# ISP_PREVIEW register map
Vendor: Texas Instruments
Peripheral module from a debugger description file (folder omap36xx).
Registers are 32-bit, read-write, reset 0x0 unless marked. A register's access mark holds for its fields unless they carry their own. Offsets are as the file gives them; lines under a group give offsets from that group; [hi:lo] are bit positions; {n}, {i} and the like mark numbered series; 'fields as' and 'values as' point back to an identical list; <NAME> marks a mode.

## ISP_PREVIEW
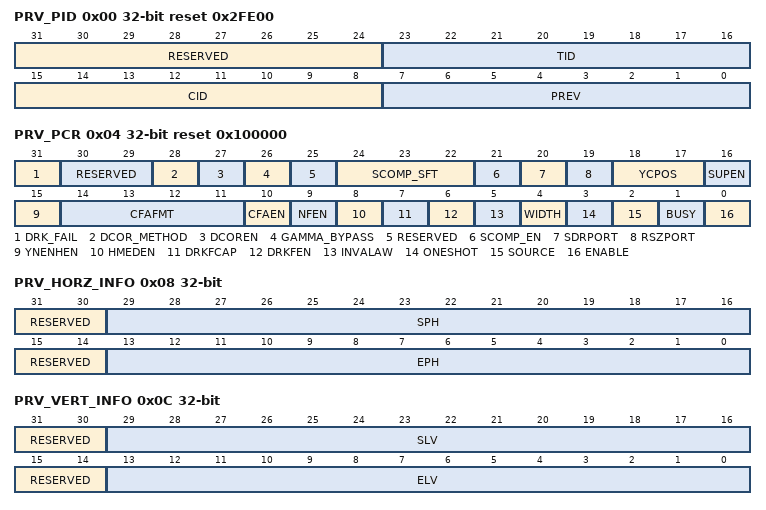
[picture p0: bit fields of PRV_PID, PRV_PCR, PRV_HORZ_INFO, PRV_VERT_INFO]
0x00 PRV_PID ro reset 0x2FE00 (reset mask 0xFFFFFF00) — PERIPHERAL ID REGISTER
  [31:24] RESERVED — Write 0s for future compatibility. Reads returns 0.
  [23:16] TID — Peripheral identification: PRV module
  [15:8] CID — Class identification: Camera ISP
  [7:0] PREV — Peripheral revision number
0x04 PRV_PCR access per field reset 0x100000 — PERIPHERAL CONTROL REGISTER All the fields in this register can be altered even when the PREVIEW module is busy. Changes take place only for the next frame.
  [31] DRK_FAIL rw — Dark frame subtract fail status. Write 1 to clear this bit. Reset to zero for the next frame. When the error is triggered, dark frame subtract is abandoned for the current frame, dark frame subtract resumes for next frame (but bit is not cleared unless explicitly done by firmware).
    0=No error; 1=Error
  [30:29] RESERVED rw — Write 0s for future compatibility.Reads returns 0.
  [28] DCOR_METHOD rw — Defect correction method.
    0=MinMax; 1=MinMax2 (Couplet defect correction)
  [27] DCOREN rw — Defect correction enable This bit enables or disables the defect correction. The PRV_PCR.DCOR_METHOD and PRV_CDC_THRx registers must be configured for correct operation.
    0=Disable defect correction; 1=Enable defect correction
  [26] GAMMA_BYPASS rw — Bypass, the output is set to the 8 MSB of the 10-bit input.
    0=No bypass; 1=Bypass, the output is set to the 8 MSB of the 10-bit input
  [25] RESERVED rw — Write 0s for future compatibility.Reads returns 0.
  [24:22] SCOMP_SFT rw — Shading compensation shift value after multiplication. The right-shift range is 0 to 7.
  [21] SCOMP_EN rw — Shading compensation enable instead of dark frame The 8-bit value loaded from memory is multiplied by the current pixel instead of subtracting it. Note that the dark frame subtract (DRKFEN) must be enabled in addition to this bit being active to perform shading compensation.
    0=Disable. Dark frame subtract can be used.; 1=Enable. Dark frame subtract cannot be used.
  [20] SDRPORT rw — PREVIEW module memory output port enable. This bit enables or disables the data transfer from the PREVIEW module to the memory.
    0=Disable; 1=Enable
  [19] RSZPORT rw — RESIZER module output port enable. This bit enables or disables the data transfer between the PREVIEW and RESIZER modules. Controls whether or not SDRAM output data is forwarded to the resizer input port. This control bit does not depend on the state of the former SDRPORT bit. Data is simultaneously written to SDRAM (if SDRPORT bit is set) while sending the same data to the resizer as input. Note that the CCDC is also capable or directly writing to the resizer input port. The CCDC setting takes precedence over the preview engine setting.
    0=Disable; 1=Enable
  [18:17] YCPOS rw — (CRYCBY) Cr0(31:24) Y1(23:16) Cb0(15:8) Y0(7:0)
    0=(YCRYCB) Y1(31:24) Cr0(23:16) Y0(15:8) Cb0(7:0); 1=(YCBYCR) Y1(31:24) Cb0(23:16) Y0(15:8) Cr0(7:0); 2=(CBYCRY) Cb0(31:24) Y1(23:16) Cr(15:8) Y0(7:0); 3=(CRYCBY) Cr0(31:24) Y1(23:16) Cb0(15:8) Y0(7:0)
  [16] SUPEN rw — Color suppression.
    0=Disable; 1=Enable
  [15] YNENHEN rw — Non-linear enhancer
    0=Disable; 1=Enable
  [14:11] CFAFMT rw — CFA format
    0=Mode 0: conventional Bayer; 1=Mode 1: horizontal 2x downsample; 2=Mode 2: bypass CFA stage; 3=Mode 3: horizontal and vertical 2x downsample; 4=Mode 4: Super CCD Honeycom movie mode sensor; 5=Mode5: bypass CFA stage 
  [10] CFAEN rw — CFA enable
    0=Disable; 1=Enable
  [9] NFEN rw — Noise filter enable
    0=Disable; 1=Enable
  [8] HMEDEN rw — Horizontal median filter enable.
    0=Disable; 1=Enable
  [7] DRKFCAP rw — Dark frame capture enable.
    0=Normal processing; 1=Capture dark frame
  [6] DRKFEN rw — Subtract dark frame enable.
    0=Disable; 1=Enable
  [5] INVALAW rw — Inverse A-Law enable.
    0=Disable; 1=Enable
  [4] WIDTH rw — Input data width selection.
    0=10-bit mode; 1=8-bit mode
  [3] ONESHOT rw — One-shot mode selection.If this bit is set to 1, it is reset to 0 after the ENABLE bit is asserted.
    0=Continuous mode (through the video port); 1=One shot mode
  [2] SOURCE rw — Input source selection.If this bit is set to 1, it is reset to 0 after the ENABLE bit is asserted.
    0=Video port (through the CCDC); 1=Memory
  [1] BUSY ro — Busy bit.
    0=PREVIEW module not busy; 1=PREVIEW module busy
  [0] ENABLE rw — Enable bit.If the ONESHOT or SOURCE bit is 1, this bit is reset to 0 after it is asserted
    0=PREVIEW module disabled; 1=PREVIEW module enabled
0x08 PRV_HORZ_INFO — HORIZONTAL SETUP REGISTER
  [31:30] RESERVED — Write 0s for future compatibility.Reads returns 0.
  [29:16] SPH — Start pixel horizontal.If PRV_PCR.SOURCE == 0 (CCDC input) SPH must be = 2.
  [15:14] RESERVED — Write 0s for future compatibility.Reads returns 0.
  [13:0] EPH — End pixel horizontal. The input width of the preview engine must be a multiple of the average count multiplied by the least common multiple of the odd distance and even distance of the AVE register settings. If PRV_PCR.SOURCE == 0 (CCDC input) EPH must be = 2 pixels before the last pixel sent from the CCDC. PRV_HORZ_INFO.EPH - PRV_HORZ_INFO.SPH + 1) MOD ((1 PRV_AVE.COUNT) * LeastCommonMultiple(PRV_AVE.ODDDIST+1, PRV_AVE.EVENDIST+1)) = 0
0x0C PRV_VERT_INFO — VERTICAL SETUP REGISTER
  [31:30] RESERVED — Write 0s for future compatibility.Reads returns 0.
  [29:16] SLV — Start line vertical
  [15:14] RESERVED — Write 0s for future compatibility.Reads returns 0.
  [13:0] ELV — End line vertical
0x10 PRV_RSDR_ADDR — MEMORY READ ADDRESS REGISTER
  [31:0] RADR — 32-bit read address. Specifies the 32-bit address in memory of the input frame. The lower 5 bits of this register are always treated as 0s. The offset should be aligned on a 32-byte boundary. This field can be altered even when the PREVIEW module is busy. The change takes place only for the next frame (next VS pulse). However, note that reading this register always gives the latest value.
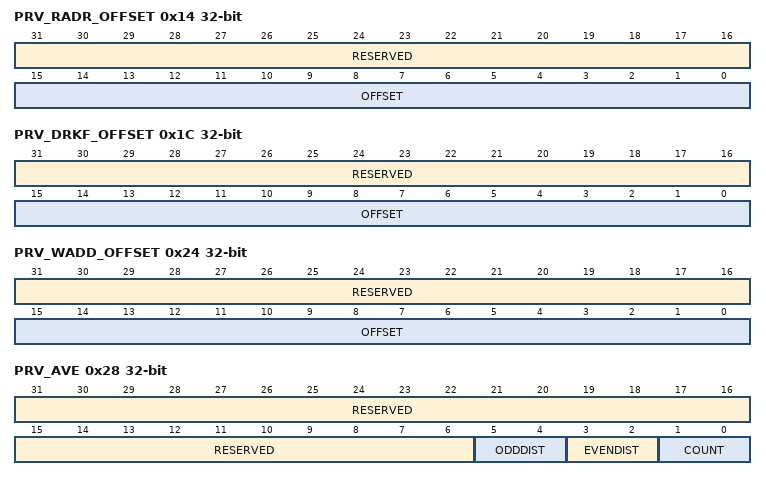
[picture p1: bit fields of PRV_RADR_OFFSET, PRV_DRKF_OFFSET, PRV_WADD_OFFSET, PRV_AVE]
0x14 PRV_RADR_OFFSET — MEMORY READ ADDRESS OFFSET REGISTER
  [31:16] RESERVED — Write 0s for future compatibility.Reads returns 0.
  [15:0] OFFSET — Line offset. Specifies the offset for each line relatively to the previous line. The lower 5 bits of this register are always treated as 0s. The offset should be aligned on a 32-byte boundary. This field can be altered even when the PREVIEW module is busy. The change takes place only for the next frame (next VS sync pulse). However, note that reading this register always gives the latest value.
0x18 PRV_DSDR_ADDR — DARK FRAME MEMORY ADDRESS REGISTER
  [31:0] DRKF — Dark frame address. Specifies the dark frame start address in memory. The lower 5 bits of this register are always treated as 0s. The offset should be aligned on a 32-byte boundary. This field can be altered even when the PREVIEW module is busy. The change takes place only for the next frame (next VS sync pulse). However, note that reading this register always gives the latest value.
0x1C PRV_DRKF_OFFSET — DARK FRAME MEMORY OFFSET REGISTER
  [31:16] RESERVED — Write 0s for future compatibility.Reads returns 0.
  [15:0] OFFSET — Dark frame line offset. Specifies the offset for each line relatively to the previous line. The lower 5 bits of this register are always treated as 0s. The offset should be aligned on a 32-byte boundary. This field can be altered even when the PREVIEW module is busy. The change takes place only for the next frame (next VS pulse). However, note that reading this register always gives the latest value.
0x20 PRV_WSDR_ADDR — MEMORY WRITE ADDRESS REGISTER
  [31:0] ADDR — Write address. Specifies the 32-bit address in memory of the output frame. The lower 5 bits of this register are always treated as 0s. The offset should be aligned on a 32-byte boundary. For optimum performance in the system, the starting address must be on a 256-byte boundary This field can be altered even when the PREVIEW module is busy. The change takes place only for the next frame (next VS pulse). However, note that reading this register always gives the latest value.
0x24 PRV_WADD_OFFSET — MEMORY WRITE OFFSET REGISTER
  [31:16] RESERVED — Write 0s for future compatibility.Reads returns 0.
  [15:0] OFFSET — Line offset. The lower 5 bits of this register are always treated as 0s. The offset should be aligned on a 32-byte boundary. For optimum performance in the system, the starting address must be on a 256-byte boundary This field can be altered even when the PREVIEW module is busy. The change takes place only for the next frame (next VS pulse). However, note that reading this register always gives the latest value.
0x28 PRV_AVE — INPUT FORMATTER REGISTER
  [31:6] RESERVED — Write 0s for future compatibility.Reads returns 0.
  [5:4] ODDDIST — Distance between consecutive pixels of the same color in the odd line.
    {v}={v+1} (v=0..3)
  [3:2] EVENDIST — Distance between consecutive pixels of the same color in the even line.
    {v}={v+1} (v=0..3)
  [1:0] COUNT — Number of horizontal pixels to average. This field should not be changed when the 'PRV_PCR.DRKFEN bit is set to 1 The input width must be divisible by the number of horizontal pixels to average indicated by this field ( if 4 pixel average is selected, then the input width must be a multiple of 4).
    0=No averaging; 1=2-pixel average; 2=4-pixel average; 3=8-pixel average
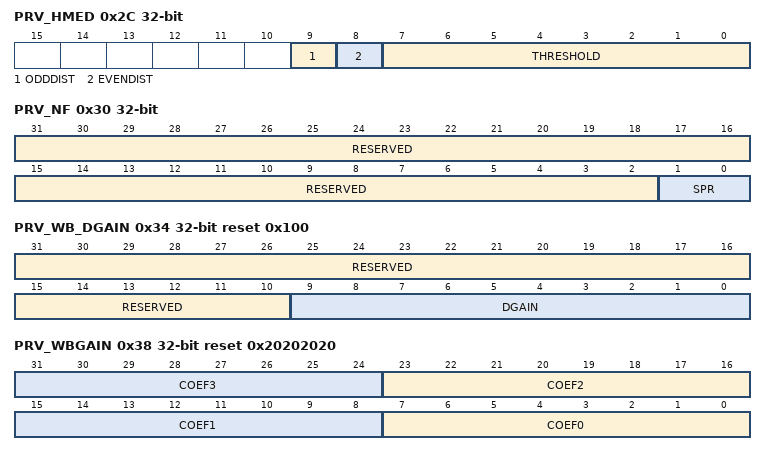
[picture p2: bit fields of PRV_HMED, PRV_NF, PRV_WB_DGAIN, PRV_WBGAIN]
0x2C PRV_HMED — HORIZONTAL MEDIAN FILTER REGISTER
  [9] ODDDIST — Distance between consecutive pixels of the same color in the odd line.
    0=1; 1=2
  [8] EVENDIST — Distance between consecutive pixels of the same color in even line.
    0=1; 1=2
  [7:0] THRESHOLD — Horizontal median filter threshold.
0x30 PRV_NF — NOISE FILTER REGISTER
  [31:2] RESERVED — Write 0s for future compatibility.Reads returns 0.
  [1:0] SPR — The spread value in noise filter algorithm
0x34 PRV_WB_DGAIN reset 0x100 — WHITE BALANCE COEF REGISTER
  [31:10] RESERVED — Write 0s for future compatibility.Reads returns 0.
  [9:0] DGAIN — Digital gain for the white balance. The data is in U10Q8 representation. The value can change anytime following the start of a frame.
0x38 PRV_WBGAIN reset 0x20202020 — WHITE BALANCE COEF REGISTER
  [8n+7:8n] COEF{n} (n=0..3) — White balance gain - COEF{n}. The data is in U8Q5 representation. The value can change anytime following the start of a frame.
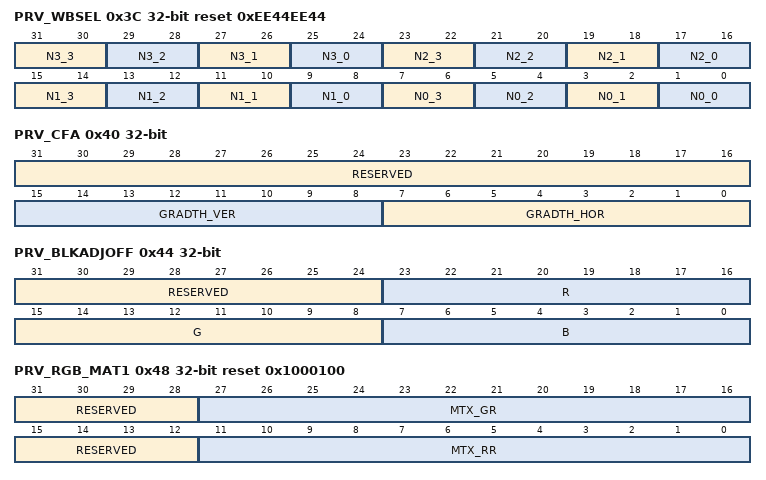
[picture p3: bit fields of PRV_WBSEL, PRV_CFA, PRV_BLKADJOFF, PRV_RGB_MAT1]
0x3C PRV_WBSEL reset 0xEE44EE44 — WHITE BALANCE COEF SELECTION REGISTER
  [all] fields
    {v}=COEF{v} (v=0..3)
  [31:30] N3_3 — Coefficient selection for 3rd line, 3rd pixel.
  [29:28] N3_2 — Coefficient selection for 3rd line, 2rd pixel.
  [27:26] N3_1 — Coefficient selection for 3rd line, 1st pixel.
  [25:24] N3_0 — Coefficient selection for 3rd line, 0th pixel.
  [23:22] N2_3 — Coefficient selection for 2nd line, 3rd pixel.
  [21:20] N2_2 — Coefficient selection for 2nd line, 2nd pixel.
  [19:18] N2_1 — Coefficient selection for 2nd line, 1st pixel.
  [17:16] N2_0 — Coefficient selection for 2nd line, 0th pixel.
  [15:14] N1_3 — Coefficient selection for 1st line, 3rd pixel.
  [13:12] N1_2 — Coefficient selection for 1st line, 2nd pixel.
  [11:10] N1_1 — Coefficient selection for 1st line, 1st pixel.
  [9:8] N1_0 — Coefficient selection for 1st line, 0th pixel.
  [7:6] N0_3 — Coefficient selection for 0th line, 3rd pixel.
  [5:4] N0_2 — Coefficient selection for 0th line, 2nd pixel.
  [3:2] N0_1 — Coefficient selection for 0th line, 1st pixel.
  [1:0] N0_0 — Coefficient selection for 0th line, 0th pixel.
0x40 PRV_CFA — COLOR FILTER ARRAY REGISTER
  [31:16] RESERVED — Write 0s for future compatibility.Reads returns 0.
  [15:8] GRADTH_VER — Gradient threshold vertical.
  [7:0] GRADTH_HOR — Gradient threshold horizontal.
0x44 PRV_BLKADJOFF — BLACK ADJUSTMENT OFFSET REGISTER
  [31:24] RESERVED — Write 0s for future compatibility.Reads returns 0.
  [23:16] R — Black-level offset adjustment for RED. The data is in 2's complement format.
  [15:8] G — Black-level offset adjustment for GREEN. The data is in 2's complement format.
  [7:0] B — Black-level offset adjustment for BLUE. The data is in 2's complement format.
0x48 PRV_RGB_MAT1 reset 0x1000100 — RGB TO RGB MATRIX COEF REGISTER
  [31:28] RESERVED — Write 0s for future compatibility.Reads returns 0.
  [27:16] MTX_GR — Blending value for GR position. The format is in S12Q8 representation.
  [15:12] RESERVED — Write 0s for future compatibility.Reads returns 0.
  [11:0] MTX_RR — Blending value for RR position. The format is in S12Q8 representation.
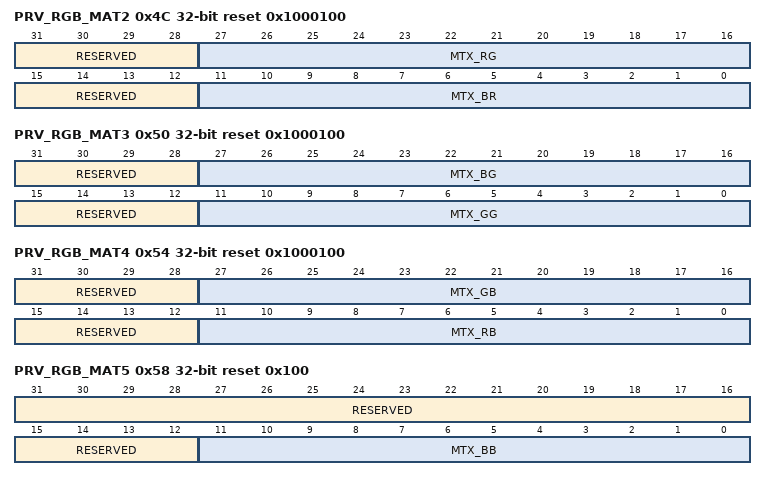
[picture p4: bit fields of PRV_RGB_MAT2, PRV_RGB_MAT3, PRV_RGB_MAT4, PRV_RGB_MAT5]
0x4C PRV_RGB_MAT2 reset 0x1000100 — RGB TO RGB MATRIX COEF REGISTER
  [31:28] RESERVED — Write 0s for future compatibility.Reads returns 0.
  [27:16] MTX_RG — Blending value for RG position. The format is in S12Q8 representation.
  [15:12] RESERVED — Write 0s for future compatibility.Reads returns 0.
  [11:0] MTX_BR — Blending value for BR position. The format is in S12Q8 representation.
0x50 PRV_RGB_MAT3 reset 0x1000100 — RGB TO RGB MATRIX COEF REGISTER
  [31:28] RESERVED — Write 0s for future compatibility.Reads returns 0.
  [27:16] MTX_BG — Blending value for BG position. The format is in S12Q8 representation.
  [15:12] RESERVED — Write 0s for future compatibility.Reads returns 0.
  [11:0] MTX_GG — Blending value for GG position. The format is in S12Q8 representation.
0x54 PRV_RGB_MAT4 reset 0x1000100 — RGB TO RGB MATRIX COEF REGISTER
  [31:28] RESERVED — Write 0s for future compatibility.Reads returns 0.
  [27:16] MTX_GB — Blending value for GB position. The format is in S12Q8 representation.
  [15:12] RESERVED — Write 0s for future compatibility.Reads returns 0.
  [11:0] MTX_RB — Blending value for RB position. The format is in S12Q8 representation.
0x58 PRV_RGB_MAT5 reset 0x100 — RGB TO RGB MATRIX COEF REGISTER
  [31:12] RESERVED — Write 0s for future compatibility.Reads returns 0.
  [11:0] MTX_BB — Blending value for BB position. The format is in S12Q8 representation.
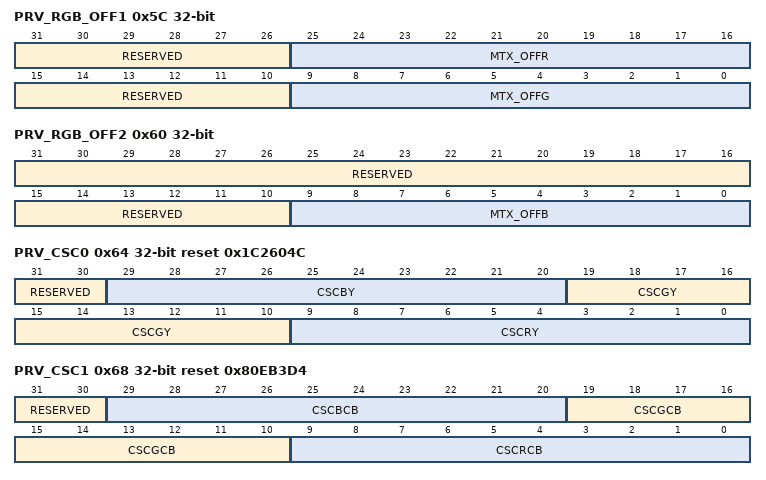
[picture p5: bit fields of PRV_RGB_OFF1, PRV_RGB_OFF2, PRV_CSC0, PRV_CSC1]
0x5C PRV_RGB_OFF1 — RGB TO RGB MATRIX OFFSET REGISTER
  [31:26] RESERVED — Write 0s for future compatibility.Reads returns 0.
  [25:16] MTX_OFFR — Blending offset value for RED. The data is in 2's complement format.
  [15:10] RESERVED — Write 0s for future compatibility.Reads returns 0.
  [9:0] MTX_OFFG — Blending offset value for GREEN. The data is in 2's complement format.
0x60 PRV_RGB_OFF2 — RGB TO RGB MATRIX OFFSET REGISTER
  [31:10] RESERVED — Write 0s for future compatibility.Reads returns 0.
  [9:0] MTX_OFFB — Blending offset value for BLUE (in 2's complemented representation).
0x64 PRV_CSC0 reset 0x1C2604C — COLOR SPACE CONVERSION COEF REGISTER
  [31:30] RESERVED — Write 0s for future compatibility.Reads returns 0.
  [29:20] CSCBY — Color space conversion coefficient of BLUE for computing Y. The format is in S10Q8 representation.
  [19:10] CSCGY — Color space conversion coefficient of GREEN for computing Y. The format is in S10Q8 representation.
  [9:0] CSCRY — Color space conversion coefficient of RED for computing Y. The format is in S10Q8 representation.
0x68 PRV_CSC1 reset 0x80EB3D4 — COLOR SPACE CONVERSION COEF REGISTER
  [31:30] RESERVED — Write 0s for future compatibility.Reads returns 0.
  [29:20] CSCBCB — Color space conversion coefficient of BLUE for computing Y. The format is in S10Q8 representation.
  [19:10] CSCGCB — Color space conversion coefficient of GREEN for computing Y. The format is in S10Q8 representation.
  [9:0] CSCRCB — Color space conversion coefficient of RED for computing Cb. The format is in S10Q8 representation.
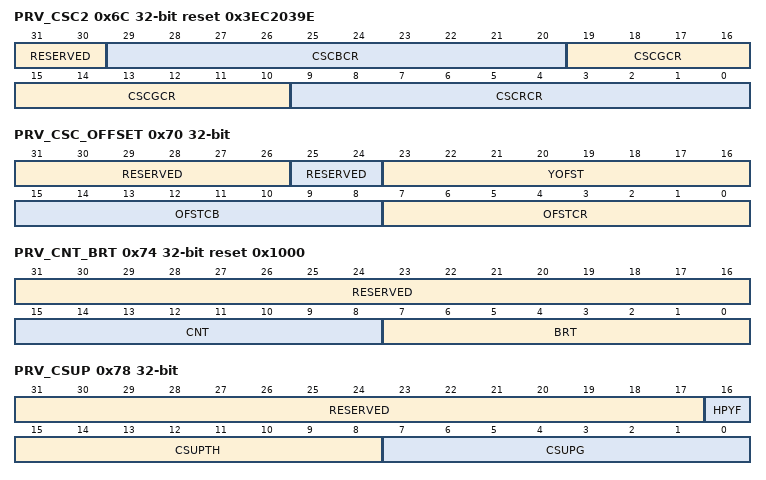
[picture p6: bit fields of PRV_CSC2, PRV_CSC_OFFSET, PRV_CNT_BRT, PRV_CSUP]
0x6C PRV_CSC2 reset 0x3EC2039E — COLOR SPACE CONVERSION COEF REGISTER
  [31:30] RESERVED — Write 0s for future compatibility.Reads returns 0.
  [29:20] CSCBCR — Color space conversion coefficient of BLUE for computing Cr. The format is in S10Q8 representation.
  [19:10] CSCGCR — Color space conversion coefficient of GREEN for computing Cr. The format is in S10Q8 representation.
  [9:0] CSCRCR — Color space conversion coefficient of RED for computing Cr. The format is in S10Q8 representation.
0x70 PRV_CSC_OFFSET — COLOR SPACE CONVERSION OFFSET REGISTER
  [31:26] RESERVED — Write 0s for future compatibility.Reads returns 0.
  [25:24] RESERVED — Write 0s for future compatibility.Reads returns written value.
  [23:16] YOFST — DC offset value for Y component. The data is in S8Q0 representation. Yout = Yin + YOFST
  [15:8] OFSTCB — DC offset value for Cb component. The data is in S8Q0 representation. Cout = Cin + OFSTCB
  [7:0] OFSTCR — DC offset value for Cr component. The data is in S8Q0 representation. Cout = Cin + OFSTCR
0x74 PRV_CNT_BRT reset 0x1000 — CONTRAST SET REGISTER
  [31:16] RESERVED — Write 0s for future compatibility.Reads returns 0.
  [15:8] CNT — Contrast adjustment. Sets the contrast of the Y data. The data is in U8Q4 representation i.e (0 to 15.9375).. Applied after offset adjustment.
  [7:0] BRT — Brightness adjustment. Sets the brightness of Y data. The data is in U8Q0 representation (0 to 255).. Applied after contrast adjustment.
0x78 PRV_CSUP — CHROMINANCE SUPPRESSION SET REGISTER
  [31:17] RESERVED — Write 0s for future compatibility.Reads returns 0.
  [16] HPYF — Use high-pass filter of luminance for chroma suppression
    0=Disable. Use luminance without high-pass filter.; 1=Enable
  [15:8] CSUPTH — Chroma suppression threshold.
  [7:0] CSUPG — Gain value for chroma suppression function. The data format is in U8Q8 representation.
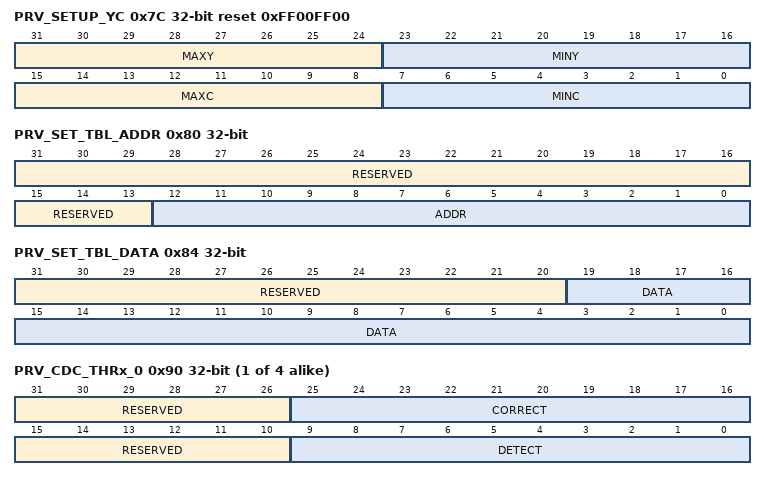
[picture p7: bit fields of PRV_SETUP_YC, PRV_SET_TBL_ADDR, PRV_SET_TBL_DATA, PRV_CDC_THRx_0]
0x7C PRV_SETUP_YC reset 0xFF00FF00 — Y AND C SET REGISTER
  [31:24] MAXY — Maximum Y value. The values greater than MAXY are clipped to MAXY.
  [23:16] MINY — Minimum Y value. The values smaller than MINY are clipped to MINY.
  [15:8] MAXC — Maximum Cb and Cr values. The values greater than MAXC are clipped to MAXC.
  [7:0] MINC — Minimum Cb and Cr values. The values smaller than MINC are clipped to MINC.
0x80 PRV_SET_TBL_ADDR — SET TABLE ADDRESS REGISTER
  [31:13] RESERVED — Write 0s for future compatibility.Reads returns 0.
  [12:0] ADDR — 13-bit address.
0x84 PRV_SET_TBL_DATA (reset mask 0xFFF00000) — SETUP TABLE DATA REGISTER
  [31:20] RESERVED — Write 0s for future compatibility.Reads returns 0.
  [19:0] DATA — Data to be written. All 20 bits are valid to set up the non-linear enhancer table. Only 8 LSBs are valid to set up the gamma, noise filter and CFA coefficient tables.
{0x90+4i} PRV_CDC_THRx_{i} (i=0..3) — COUPLET DEFECT CORRECTION THRESHOLD REGISTER FOR COLORx
  [31:26] RESERVED — Write 0s for future compatibility.Reads returns 0.
  [25:16] CORRECT — Correction threshold when couplet defect correction is selected. It must be set to 1023 for single defect correction.
  [15:10] RESERVED — Write 0s for future compatibility.Reads returns 0.
  [9:0] DETECT — Detection threshold when couplet defect correction is selected. It must be set to 0 for single defect correction.
